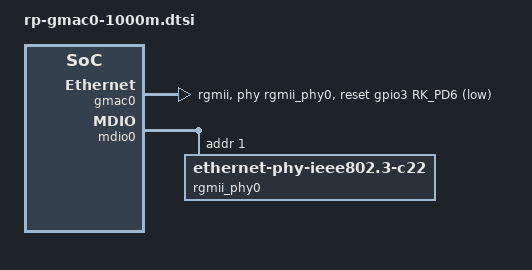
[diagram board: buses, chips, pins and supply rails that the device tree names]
&gmac0 {
    phy-mode = "rgmii";
    clock_in_out = "output";
    snps,reset-gpio = <&gpio3 RK_PD6 GPIO_ACTIVE_LOW>;
    snps,reset-active-low;
    /* Reset time is 20ms, 100ms for rtl8211f */
    snps,reset-delays-us = <0 20000 100000>;

    pinctrl-names = "default";
    pinctrl-0 = <&eth0m0_miim
             &eth0m0_tx_bus2
             &eth0m0_rx_bus2
             &eth0m0_rgmii_clk
             &eth0m0_rgmii_bus
             &ethm0_clk0_25m_out>;

    tx_delay = <0x1a>;
    rx_delay = <0x21>;

    phy-handle = <&rgmii_phy0>;
    status = "okay";
};

&mdio0 {
    rgmii_phy0: phy@1 {
        compatible = "ethernet-phy-ieee802.3-c22";
        reg = <0x1>;
        clocks = <&cru REFCLKO25M_GMAC0_OUT>;
    };
};
